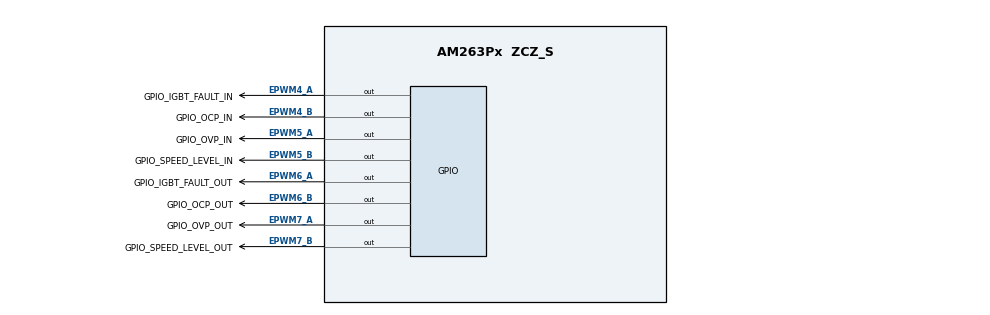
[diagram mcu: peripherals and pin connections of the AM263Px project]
/**
 * @cliArgs --device "AM263Px" --package "ZCZ_S" --part "AM263P4" --context "r5fss0-0" --product "MCU_PLUS_SDK@07.03.01"
 * @versions {"tool":"1.18.0+3266"}
 */

/**
 * Import the modules used in this configuration.
 */
const pmic            = scripting.addModule("/board/pmic/pmic", {}, false);
const pmic1           = pmic.addInstance();
const epwm            = scripting.addModule("/drivers/epwm/epwm", {}, false);
const epwm1           = epwm.addInstance();
const epwm2           = epwm.addInstance();
const epwm3           = epwm.addInstance();
const gpio            = scripting.addModule("/drivers/gpio/gpio", {}, false);
const gpio1           = gpio.addInstance();
const gpio2           = gpio.addInstance();
const gpio3           = gpio.addInstance();
const gpio4           = gpio.addInstance();
const gpio5           = gpio.addInstance();
const gpio6           = gpio.addInstance();
const gpio7           = gpio.addInstance();
const gpio8           = gpio.addInstance();
const mcspi           = scripting.addModule("/drivers/mcspi/mcspi", {}, false);
const mcspi1          = mcspi.addInstance();
const debug_log       = scripting.addModule("/kernel/dpl/debug_log");
const mpu_armv7       = scripting.addModule("/kernel/dpl/mpu_armv7", {}, false);
const mpu_armv71      = mpu_armv7.addInstance();
const mpu_armv72      = mpu_armv7.addInstance();
const mpu_armv73      = mpu_armv7.addInstance();
const mpu_armv74      = mpu_armv7.addInstance();
const default_linker  = scripting.addModule("/memory_configurator/default_linker", {}, false);
const default_linker1 = default_linker.addInstance();
const general         = scripting.addModule("/memory_configurator/general", {}, false);
const general1        = general.addInstance();
const region          = scripting.addModule("/memory_configurator/region", {}, false);
const region1         = region.addInstance();
const section         = scripting.addModule("/memory_configurator/section", {}, false);
const section1        = section.addInstance();
const section2        = section.addInstance();
const section3        = section.addInstance();
const section4        = section.addInstance();
const section5        = section.addInstance();
const section6        = section.addInstance();
const section7        = section.addInstance();
const section8        = section.addInstance();
const section9        = section.addInstance();
const section10       = section.addInstance();
const section11       = section.addInstance();
const section12       = section.addInstance();
const epwm_xbar       = scripting.addModule("/xbar/epwm_xbar/epwm_xbar", {}, false);
const epwm_xbar1      = epwm_xbar.addInstance();
const epwm_xbar2      = epwm_xbar.addInstance();
const epwm_xbar3      = epwm_xbar.addInstance();
const epwm_xbar4      = epwm_xbar.addInstance();
const epwm_xbar5      = epwm_xbar.addInstance();
const epwm_xbar6      = epwm_xbar.addInstance();
const epwm_xbar7      = epwm_xbar.addInstance();
const epwm_xbar8      = epwm_xbar.addInstance();
const int_xbar        = scripting.addModule("/xbar/int_xbar/int_xbar", {}, false);
const int_xbar1       = int_xbar.addInstance();

/**
 * Write custom configuration values to the imported modules.
 */
pmic1.$name = "CONFIG_PMIC0";

epwm1.epwmTimebase_emulationMode                               = "EPWM_EMULATION_FREE_RUN";
epwm1.epwmTimebase_period                                      = 10000;
epwm1.epwmTimebase_counterMode                                 = "EPWM_COUNTER_MODE_UP";
epwm1.epwmTimebase_syncOutPulseMode                            = ["EPWM_SYNC_OUT_PULSE_ON_ALL"];
epwm1.epwmCounterCompare_cmpA                                  = 7000;
epwm1.epwmCounterCompare_cmpB                                  = 7000;
epwm1.epwmActionQualifier_EPWM_AQ_OUTPUT_A_usedEvents          = ["EPWM_AQ_OUTPUT_ON_TIMEBASE_UP_CMPA","EPWM_AQ_OUTPUT_ON_TIMEBASE_ZERO"];
epwm1.epwmActionQualifier_EPWM_AQ_OUTPUT_B_usedEvents          = ["EPWM_AQ_OUTPUT_ON_TIMEBASE_UP_CMPB","EPWM_AQ_OUTPUT_ON_TIMEBASE_ZERO"];
epwm1.epwmActionQualifier_EPWM_AQ_OUTPUT_A_ON_TIMEBASE_ZERO    = "EPWM_AQ_OUTPUT_HIGH";
epwm1.epwmActionQualifier_EPWM_AQ_OUTPUT_A_ON_TIMEBASE_UP_CMPA = "EPWM_AQ_OUTPUT_LOW";
epwm1.epwmActionQualifier_EPWM_AQ_OUTPUT_B_ON_TIMEBASE_ZERO    = "EPWM_AQ_OUTPUT_LOW";
epwm1.epwmActionQualifier_EPWM_AQ_OUTPUT_B_ON_TIMEBASE_UP_CMPB = "EPWM_AQ_OUTPUT_HIGH";
epwm1.epwmEventTrigger_enableInterrupt                         = true;
epwm1.epwmEventTrigger_interruptEventCount                     = "1";
epwm1.epwmTripZone_EPWM_TZ_ACTION_EVENT_DCAEVT1                = "EPWM_TZ_ACTION_HIGH";
epwm1.epwmTripZone_EPWM_TZ_ACTION_EVENT_DCAEVT2                = "EPWM_TZ_ACTION_LOW";
epwm1.epwmTripZone_EPWM_TZ_ACTION_EVENT_DCBEVT1                = "EPWM_TZ_ACTION_HIGH";
epwm1.epwmTripZone_EPWM_TZ_ACTION_EVENT_DCBEVT2                = "EPWM_TZ_ACTION_LOW";
epwm1.epwmDigitalCompare_EPWM_TZ_DC_OUTPUT_A1                  = "EPWM_TZ_EVENT_DCXH_HIGH";
epwm1.epwmDigitalCompare_EPWM_TZ_DC_OUTPUT_A2                  = "EPWM_TZ_EVENT_DCXL_HIGH";
epwm1.epwmDigitalCompare_EPWM_TZ_DC_OUTPUT_B1                  = "EPWM_TZ_EVENT_DCXH_HIGH";
epwm1.epwmDigitalCompare_EPWM_TZ_DC_OUTPUT_B2                  = "EPWM_TZ_EVENT_DCXL_HIGH";
epwm1.epwmDigitalCompare_EPWM_DC_TYPE_DCAH                     = "EPWM_DC_TRIP_TRIPIN5";
epwm1.epwmDigitalCompare_EPWM_DC_TYPE_DCAL                     = "EPWM_DC_TRIP_TRIPIN6";
epwm1.epwmDigitalCompare_EPWM_DC_TYPE_DCBH                     = "EPWM_DC_TRIP_TRIPIN7";
epwm1.epwmDigitalCompare_EPWM_DC_TYPE_DCBL                     = "EPWM_DC_TRIP_TRIPIN8";
epwm1.$name                                                    = "CONFIG_PWM0";
epwm1.epwmDeadband_polarityFED                                 = "EPWM_DB_POLARITY_ACTIVE_LOW";
epwm1.epwmDeadband_enableRED                                   = true;
epwm1.epwmDeadband_enableFED                                   = true;
epwm1.epwmDeadband_delayRED                                    = 100;
epwm1.epwmDeadband_delayFED                                    = 100;
epwm1.EPWM.$assign                                             = "EPWM0";

epwm2.$name                                                    = "CONFIG_PWM1";
epwm2.epwmTimebase_counterMode                                 = "EPWM_COUNTER_MODE_UP";
epwm2.epwmTimebase_period                                      = 10000;
epwm2.epwmCounterCompare_cmpA                                  = 7000;
epwm2.epwmCounterCompare_cmpB                                  = 7000;
epwm2.epwmActionQualifier_EPWM_AQ_OUTPUT_A_usedEvents          = ["EPWM_AQ_OUTPUT_ON_TIMEBASE_UP_CMPA","EPWM_AQ_OUTPUT_ON_TIMEBASE_ZERO"];
epwm2.epwmActionQualifier_EPWM_AQ_OUTPUT_B_usedEvents          = ["EPWM_AQ_OUTPUT_ON_TIMEBASE_UP_CMPB","EPWM_AQ_OUTPUT_ON_TIMEBASE_ZERO"];
epwm2.epwmActionQualifier_EPWM_AQ_OUTPUT_A_ON_TIMEBASE_ZERO    = "EPWM_AQ_OUTPUT_HIGH";
epwm2.epwmActionQualifier_EPWM_AQ_OUTPUT_A_ON_TIMEBASE_UP_CMPA = "EPWM_AQ_OUTPUT_LOW";
epwm2.epwmActionQualifier_EPWM_AQ_OUTPUT_B_ON_TIMEBASE_ZERO    = "EPWM_AQ_OUTPUT_LOW";
epwm2.epwmActionQualifier_EPWM_AQ_OUTPUT_B_ON_TIMEBASE_UP_CMPB = "EPWM_AQ_OUTPUT_HIGH";
epwm2.epwmTripZone_EPWM_TZ_ACTION_EVENT_DCAEVT1                = "EPWM_TZ_ACTION_HIGH";
epwm2.epwmTripZone_EPWM_TZ_ACTION_EVENT_DCAEVT2                = "EPWM_TZ_ACTION_LOW";
epwm2.epwmTripZone_EPWM_TZ_ACTION_EVENT_DCBEVT1                = "EPWM_TZ_ACTION_HIGH";
epwm2.epwmTripZone_EPWM_TZ_ACTION_EVENT_DCBEVT2                = "EPWM_TZ_ACTION_LOW";
epwm2.epwmDigitalCompare_EPWM_TZ_DC_OUTPUT_A1                  = "EPWM_TZ_EVENT_DCXH_HIGH";
epwm2.epwmDigitalCompare_EPWM_TZ_DC_OUTPUT_A2                  = "EPWM_TZ_EVENT_DCXL_HIGH";
epwm2.epwmDigitalCompare_EPWM_TZ_DC_OUTPUT_B1                  = "EPWM_TZ_EVENT_DCXH_HIGH";
epwm2.epwmDigitalCompare_EPWM_TZ_DC_OUTPUT_B2                  = "EPWM_TZ_EVENT_DCXL_HIGH";
epwm2.epwmDigitalCompare_EPWM_DC_TYPE_DCAH                     = "EPWM_DC_TRIP_TRIPIN5";
epwm2.epwmDigitalCompare_EPWM_DC_TYPE_DCAL                     = "EPWM_DC_TRIP_TRIPIN6";
epwm2.epwmDigitalCompare_EPWM_DC_TYPE_DCBH                     = "EPWM_DC_TRIP_TRIPIN7";
epwm2.epwmDigitalCompare_EPWM_DC_TYPE_DCBL                     = "EPWM_DC_TRIP_TRIPIN8";
epwm2.epwmDeadband_polarityFED                                 = "EPWM_DB_POLARITY_ACTIVE_LOW";
epwm2.epwmDeadband_enableRED                                   = true;
epwm2.epwmDeadband_enableFED                                   = true;
epwm2.epwmDeadband_delayRED                                    = 100;
epwm2.epwmDeadband_delayFED                                    = 100;
epwm2.EPWM.$assign                                             = "EPWM1";

epwm3.$name                                                    = "CONFIG_PWM2";
epwm3.epwmTimebase_counterMode                                 = "EPWM_COUNTER_MODE_UP";
epwm3.epwmTimebase_period                                      = 10000;
epwm3.epwmCounterCompare_cmpA                                  = 7000;
epwm3.epwmCounterCompare_cmpB                                  = 7000;
epwm3.epwmActionQualifier_EPWM_AQ_OUTPUT_A_usedEvents          = ["EPWM_AQ_OUTPUT_ON_TIMEBASE_UP_CMPA","EPWM_AQ_OUTPUT_ON_TIMEBASE_ZERO"];
epwm3.epwmActionQualifier_EPWM_AQ_OUTPUT_B_usedEvents          = ["EPWM_AQ_OUTPUT_ON_TIMEBASE_UP_CMPB","EPWM_AQ_OUTPUT_ON_TIMEBASE_ZERO"];
epwm3.epwmActionQualifier_EPWM_AQ_OUTPUT_A_ON_TIMEBASE_ZERO    = "EPWM_AQ_OUTPUT_HIGH";
epwm3.epwmActionQualifier_EPWM_AQ_OUTPUT_A_ON_TIMEBASE_UP_CMPA = "EPWM_AQ_OUTPUT_LOW";
epwm3.epwmActionQualifier_EPWM_AQ_OUTPUT_B_ON_TIMEBASE_ZERO    = "EPWM_AQ_OUTPUT_LOW";
epwm3.epwmActionQualifier_EPWM_AQ_OUTPUT_B_ON_TIMEBASE_UP_CMPB = "EPWM_AQ_OUTPUT_HIGH";
epwm3.epwmTripZone_EPWM_TZ_ACTION_EVENT_DCAEVT1                = "EPWM_TZ_ACTION_HIGH";
epwm3.epwmTripZone_EPWM_TZ_ACTION_EVENT_DCAEVT2                = "EPWM_TZ_ACTION_LOW";
epwm3.epwmTripZone_EPWM_TZ_ACTION_EVENT_DCBEVT1                = "EPWM_TZ_ACTION_HIGH";
epwm3.epwmTripZone_EPWM_TZ_ACTION_EVENT_DCBEVT2                = "EPWM_TZ_ACTION_LOW";
epwm3.epwmDigitalCompare_EPWM_TZ_DC_OUTPUT_A1                  = "EPWM_TZ_EVENT_DCXH_HIGH";
epwm3.epwmDigitalCompare_EPWM_TZ_DC_OUTPUT_A2                  = "EPWM_TZ_EVENT_DCXL_HIGH";
epwm3.epwmDigitalCompare_EPWM_TZ_DC_OUTPUT_B1                  = "EPWM_TZ_EVENT_DCXH_HIGH";
epwm3.epwmDigitalCompare_EPWM_TZ_DC_OUTPUT_B2                  = "EPWM_TZ_EVENT_DCXL_HIGH";
epwm3.epwmDigitalCompare_EPWM_DC_TYPE_DCAH                     = "EPWM_DC_TRIP_TRIPIN5";
epwm3.epwmDigitalCompare_EPWM_DC_TYPE_DCAL                     = "EPWM_DC_TRIP_TRIPIN6";
epwm3.epwmDigitalCompare_EPWM_DC_TYPE_DCBH                     = "EPWM_DC_TRIP_TRIPIN7";
epwm3.epwmDigitalCompare_EPWM_DC_TYPE_DCBL                     = "EPWM_DC_TRIP_TRIPIN8";
epwm3.epwmDeadband_polarityFED                                 = "EPWM_DB_POLARITY_ACTIVE_LOW";
epwm3.epwmDeadband_enableRED                                   = true;
epwm3.epwmDeadband_enableFED                                   = true;
epwm3.epwmDeadband_delayRED                                    = 100;
epwm3.epwmDeadband_delayFED                                    = 100;
epwm3.EPWM.$assign                                             = "EPWM2";

gpio1.$name                = "GPIO_IGBT_FAULT_IN";
gpio1.GPIO.gpioPin.$assign = "EPWM4_A";

gpio2.$name                = "GPIO_OVP_IN";
gpio2.GPIO.$assign         = "GPIO";
gpio2.GPIO.gpioPin.$assign = "EPWM5_A";

gpio3.pinDir               = "OUTPUT";
gpio3.$name                = "GPIO_IGBT_FAULT_OUT";
gpio3.GPIO.$assign         = "GPIO";
gpio3.GPIO.gpioPin.$assign = "EPWM6_A";

gpio4.pinDir               = "OUTPUT";
gpio4.$name                = "GPIO_OVP_OUT";
gpio4.GPIO.$assign         = "GPIO";
gpio4.GPIO.gpioPin.$assign = "EPWM7_A";

gpio5.$name                = "GPIO_OCP_IN";
gpio5.GPIO.$assign         = "GPIO";
gpio5.GPIO.gpioPin.$assign = "EPWM4_B";

gpio6.$name                = "GPIO_SPEED_LEVEL_IN";
gpio6.GPIO.$assign         = "GPIO";
gpio6.GPIO.gpioPin.$assign = "EPWM5_B";

gpio7.pinDir               = "OUTPUT";
gpio7.$name                = "GPIO_OCP_OUT";
gpio7.GPIO.$assign         = "GPIO";
gpio7.GPIO.gpioPin.$assign = "EPWM6_B";

gpio8.pinDir               = "OUTPUT";
gpio8.$name                = "GPIO_SPEED_LEVEL_OUT";
gpio8.GPIO.$assign         = "GPIO";
gpio8.GPIO.gpioPin.$assign = "EPWM7_B";

mcspi1.$name                 = "CONFIG_MCSPI0";
pmic1.peripheralDriver       = mcspi1;
mcspi1.SPI.$assign           = "SPI1";
mcspi1.mcspiChannel[0].$name = "CONFIG_MCSPI_CH0";

const edma                  = scripting.addModule("/drivers/edma/edma", {}, false);
const edma1                 = edma.addInstance({}, false);
edma1.$name                 = "CONFIG_EDMA0";
mcspi1.edmaDriver           = edma1;
edma1.edmaRmDmaCh[0].$name  = "CONFIG_EDMA_RM0";
edma1.edmaRmQdmaCh[0].$name = "CONFIG_EDMA_RM1";
edma1.edmaRmTcc[0].$name    = "CONFIG_EDMA_RM2";
edma1.edmaRmParam[0].$name  = "CONFIG_EDMA_RM3";

debug_log.enableUartLog            = true;
debug_log.uartLog.$name            = "CONFIG_UART0";
debug_log.uartLog.UART.RXD.$assign = "UART0_RXD";
debug_log.uartLog.UART.TXD.$assign = "UART0_TXD";

mpu_armv71.$name             = "CONFIG_MPU_REGION0";
mpu_armv71.size              = 31;
mpu_armv71.attributes        = "Device";
mpu_armv71.accessPermissions = "Supervisor RD+WR, User RD";
mpu_armv71.allowExecute      = false;

mpu_armv72.$name             = "CONFIG_MPU_REGION1";
mpu_armv72.size              = 15;
mpu_armv72.accessPermissions = "Supervisor RD+WR, User RD";

mpu_armv73.$name             = "CONFIG_MPU_REGION2";
mpu_armv73.baseAddr          = 0x80000;
mpu_armv73.size              = 15;
mpu_armv73.accessPermissions = "Supervisor RD+WR, User RD";

mpu_armv74.$name             = "CONFIG_MPU_REGION3";
mpu_armv74.accessPermissions = "Supervisor RD+WR, User RD";
mpu_armv74.baseAddr          = 0x70000000;
mpu_armv74.size              = 21;

default_linker1.$name = "memory_configurator_default_linker0";

general1.$name        = "CONFIG_GENERAL0";
general1.linker.$name = "TIARMCLANG0";

region1.$name                                = "MEMORY_REGION_CONFIGURATION0";
region1.memory_region.create(11);
region1.memory_region[0].type                = "TCMA";
region1.memory_region[0].$name               = "R5F_VECS";
region1.memory_region[0].size                = 0x40;
region1.memory_region[0].auto                = false;
region1.memory_region[1].type                = "TCMA";
region1.memory_region[1].$name               = "R5F_TCMA";
region1.memory_region[1].size                = 0x7FC0;
region1.memory_region[2].type                = "TCMB";
region1.memory_region[2].size                = 0x8000;
region1.memory_region[2].$name               = "R5F_TCMB";
region1.memory_region[3].$name               = "SBL";
region1.memory_region[3].auto                = false;
region1.memory_region[3].size                = 0x40000;
region1.memory_region[4].$name               = "OCRAM";
region1.memory_region[4].auto                = false;
region1.memory_region[4].manualStartAddress  = 0x70040000;
region1.memory_region[4].size                = 0x40000;
region1.memory_region[5].type                = "FLASH";
region1.memory_region[5].auto                = false;
region1.memory_region[5].manualStartAddress  = 0x60100000;
region1.memory_region[5].size                = 0x80000;
region1.memory_region[5].$name               = "FLASH";
region1.memory_region[6].$name               = "USER_SHM_MEM";
region1.memory_region[6].auto                = false;
region1.memory_region[6].manualStartAddress  = 0x701D0000;
region1.memory_region[6].size                = 0x4000;
region1.memory_region[6].isShared            = true;
region1.memory_region[6].shared_cores        = ["r5fss0-1","r5fss1-0","r5fss1-1"];
region1.memory_region[7].$name               = "LOG_SHM_MEM";
region1.memory_region[7].auto                = false;
region1.memory_region[7].manualStartAddress  = 0x701D4000;
region1.memory_region[7].size                = 0x4000;
region1.memory_region[7].isShared            = true;
region1.memory_region[7].shared_cores        = ["r5fss0-1","r5fss1-0","r5fss1-1"];
region1.memory_region[8].type                = "CUSTOM";
region1.memory_region[8].$name               = "RTOS_NORTOS_IPC_SHM_MEM";
region1.memory_region[8].auto                = false;
region1.memory_region[8].manualStartAddress  = 0x72000000;
region1.memory_region[8].size                = 0x3E80;
region1.memory_region[8].isShared            = true;
region1.memory_region[8].shared_cores        = ["r5fss0-1","r5fss1-0","r5fss1-1"];
region1.memory_region[9].type                = "CUSTOM";
region1.memory_region[9].$name               = "MAILBOX_HSM";
region1.memory_region[9].auto                = false;
region1.memory_region[9].manualStartAddress  = 0x44000000;
region1.memory_region[9].size                = 0x3CE;
region1.memory_region[9].isShared            = true;
region1.memory_region[9].shared_cores        = ["r5fss0-1","r5fss1-0","r5fss1-1"];
region1.memory_region[10].type               = "CUSTOM";
region1.memory_region[10].$name              = "MAILBOX_R5F";
region1.memory_region[10].auto               = false;
region1.memory_region[10].manualStartAddress = 0x44000400;
region1.memory_region[10].size               = 0x3CE;
region1.memory_region[10].isShared           = true;
region1.memory_region[10].shared_cores       = ["r5fss0-1","r5fss1-0","r5fss1-1"];

section1.load_memory                  = "R5F_VECS";
section1.group                        = false;
section1.$name                        = "Vector Table";
section1.output_section.create(1);
section1.output_section[0].$name      = ".vectors";
section1.output_section[0].palignment = true;

section2.load_memory                  = "OCRAM";
section2.$name                        = "Text Segments";
section2.output_section.create(5);
section2.output_section[0].$name      = ".text.hwi";
section2.output_section[0].palignment = true;
section2.output_section[1].$name      = ".text.cache";
section2.output_section[1].palignment = true;
section2.output_section[2].$name      = ".text.mpu";
section2.output_section[2].palignment = true;
section2.output_section[3].$name      = ".text.boot";
section2.output_section[3].palignment = true;
section2.output_section[4].$name      = ".text:abort";
section2.output_section[4].palignment = true;

section3.load_memory                  = "OCRAM";
section3.$name                        = "Code and Read-Only Data";
section3.output_section.create(2);
section3.output_section[0].$name      = ".text";
section3.output_section[0].palignment = true;
section3.output_section[1].$name      = ".rodata";
section3.output_section[1].palignment = true;

section4.load_memory                  = "OCRAM";
section4.$name                        = "Data Segment";
section4.output_section.create(1);
section4.output_section[0].$name      = ".data";
section4.output_section[0].palignment = true;

section5.load_memory                             = "OCRAM";
section5.$name                                   = "Memory Segments";
section5.output_section.create(3);
section5.output_section[0].$name                 = ".bss";
section5.output_section[0].output_sections_start = "__BSS_START";
section5.output_section[0].output_sections_end   = "__BSS_END";
section5.output_section[0].palignment            = true;
section5.output_section[1].$name                 = ".sysmem";
section5.output_section[1].palignment            = true;
section5.output_section[2].$name                 = ".stack";
section5.output_section[2].palignment            = true;

section6.load_memory                              = "OCRAM";
section6.$name                                    = "Stack Segments";
section6.output_section.create(5);
section6.output_section[0].$name                  = ".irqstack";
section6.output_section[0].output_sections_start  = "__IRQ_STACK_START";
section6.output_section[0].output_sections_end    = "__IRQ_STACK_END";
section6.output_section[0].input_section.create(1);
section6.output_section[0].input_section[0].$name = ". = . + __IRQ_STACK_SIZE;";
section6.output_section[1].$name                  = ".fiqstack";
section6.output_section[1].output_sections_start  = "__FIQ_STACK_START";
section6.output_section[1].output_sections_end    = "__FIQ_STACK_END";
section6.output_section[1].input_section.create(1);
section6.output_section[1].input_section[0].$name = ". = . + __FIQ_STACK_SIZE;";
section6.output_section[2].$name                  = ".svcstack";
section6.output_section[2].output_sections_start  = "__SVC_STACK_START";
section6.output_section[2].output_sections_end    = "__SVC_STACK_END";
section6.output_section[2].input_section.create(1);
section6.output_section[2].input_section[0].$name = ". = . + __SVC_STACK_SIZE;";
section6.output_section[3].$name                  = ".abortstack";
section6.output_section[3].output_sections_start  = "__ABORT_STACK_START";
section6.output_section[3].output_sections_end    = "__ABORT_STACK_END";
section6.output_section[3].input_section.create(1);
section6.output_section[3].input_section[0].$name = ". = . + __ABORT_STACK_SIZE;";
section6.output_section[4].$name                  = ".undefinedstack";
section6.output_section[4].output_sections_start  = "__UNDEFINED_STACK_START";
section6.output_section[4].output_sections_end    = "__UNDEFINED_STACK_END";
section6.output_section[4].input_section.create(1);
section6.output_section[4].input_section[0].$name = ". = . + __UNDEFINED_STACK_SIZE;";

section7.load_memory                  = "OCRAM";
section7.$name                        = "Initialization and Exception Handling";
section7.output_section.create(3);
section7.output_section[0].$name      = ".ARM.exidx";
section7.output_section[0].palignment = true;
section7.output_section[1].$name      = ".init_array";
section7.output_section[1].palignment = true;
section7.output_section[2].$name      = ".fini_array";
section7.output_section[2].palignment = true;

section8.load_memory                 = "USER_SHM_MEM";
section8.type                        = "NOLOAD";
section8.$name                       = "User Shared Memory";
section8.group                       = false;
section8.output_section.create(1);
section8.output_section[0].$name     = ".bss.user_shared_mem";
section8.output_section[0].alignment = 0;

section9.load_memory                 = "LOG_SHM_MEM";
section9.$name                       = "Log Shared Memory";
section9.group                       = false;
section9.type                        = "NOLOAD";
section9.output_section.create(1);
section9.output_section[0].$name     = ".bss.log_shared_mem";
section9.output_section[0].alignment = 0;

section10.load_memory                 = "RTOS_NORTOS_IPC_SHM_MEM";
section10.type                        = "NOLOAD";
section10.$name                       = "IPC Shared Memory";
section10.group                       = false;
section10.output_section.create(1);
section10.output_section[0].$name     = ".bss.ipc_vring_mem";
section10.output_section[0].alignment = 0;

section11.load_memory                 = "MAILBOX_HSM";
section11.type                        = "NOLOAD";
section11.$name                       = "SIPC HSM Queue Memory";
section11.group                       = false;
section11.output_section.create(1);
section11.output_section[0].$name     = ".bss.sipc_hsm_queue_mem";
section11.output_section[0].alignment = 0;

section12.load_memory                 = "MAILBOX_R5F";
section12.$name                       = "SIPC R5F Queue Memory";
section12.group                       = false;
section12.type                        = "NOLOAD";
section12.output_section.create(1);
section12.output_section[0].$name     = ".bss.sipc_r5f_queue_mem";
section12.output_section[0].alignment = 0;

epwm_xbar1.$name                 = "CONFIG_EPWM_XBAR0_INPUTXBAR_TO_ICSSGPI";
epwm_xbar1.xbarOutput            = ["GPIO51"];
epwm_xbar1["xbarConfig-0"].$name = "CONFIG_INPUT_XBAR0";

epwm_xbar2.instance                 = "EPWM_XBAR_1";
epwm_xbar2.$name                    = "CONFIG_EPWM_XBAR1_INPUTXBAR_TO_ICSSGPI";
epwm_xbar2.xbarOutput               = ["GPIO52"];
epwm_xbar2["xbarConfig-0"].$name    = "CONFIG_INPUT_XBAR1";
epwm_xbar2["xbarConfig-0"].instance = "INPUT_XBAR_1";

epwm_xbar3.instance                 = "EPWM_XBAR_2";
epwm_xbar3.$name                    = "CONFIG_EPWM_XBAR2_INPUTXBAR_TO_ICSSGPI";
epwm_xbar3.xbarOutput               = ["GPIO53"];
epwm_xbar3["xbarConfig-0"].$name    = "CONFIG_INPUT_XBAR2";
epwm_xbar3["xbarConfig-0"].instance = "INPUT_XBAR_2";

epwm_xbar4.instance                 = "EPWM_XBAR_3";
epwm_xbar4.$name                    = "CONFIG_EPWM_XBAR3_INPUTXBAR_TO_ICSSGPI";
epwm_xbar4.xbarOutput               = ["GPIO54"];
epwm_xbar4["xbarConfig-0"].$name    = "CONFIG_INPUT_XBAR3";
epwm_xbar4["xbarConfig-0"].instance = "INPUT_XBAR_3";

epwm_xbar5.xbarOutput               = ["ICSSGPO0_PORT0"];
epwm_xbar5.instance                 = "EPWM_XBAR_4";
epwm_xbar5.$name                    = "CONFIG_EPWM_XBAR4_INPUTXBAR_TO_EPWM";
epwm_xbar5["xbarConfig-0"].instance = "INPUT_XBAR_4";
epwm_xbar5["xbarConfig-0"].$name    = "CONFIG_INPUT_XBAR4_ICSSGPO_TO_PWMXBAR";

epwm_xbar6.xbarOutput               = ["ICSSGPO1_PORT0"];
epwm_xbar6.instance                 = "EPWM_XBAR_5";
epwm_xbar6.$name                    = "CONFIG_EPWM_XBAR5_INPUTXBAR_TO_EPWM";
epwm_xbar6["xbarConfig-0"].instance = "INPUT_XBAR_5";
epwm_xbar6["xbarConfig-0"].$name    = "CONFIG_INPUT_XBAR5_ICSSGPO_TO_PWMXBAR";

epwm_xbar7.xbarOutput               = ["ICSSGPO2_PORT0"];
epwm_xbar7.instance                 = "EPWM_XBAR_6";
epwm_xbar7.$name                    = "CONFIG_EPWM_XBAR6_INPUTXBAR_TO_EPWM";
epwm_xbar7["xbarConfig-0"].instance = "INPUT_XBAR_6";
epwm_xbar7["xbarConfig-0"].$name    = "CONFIG_INPUT_XBAR6_ICSSGPO_TO_PWMXBAR";

epwm_xbar8.xbarOutput               = ["ICSSGPO3_PORT0"];
epwm_xbar8.instance                 = "EPWM_XBAR_7";
epwm_xbar8.$name                    = "CONFIG_EPWM_XBAR7_INPUTXBAR_TO_EPWM";
epwm_xbar8["xbarConfig-0"].instance = "INPUT_XBAR_7";
epwm_xbar8["xbarConfig-0"].$name    = "CONFIG_INPUT_XBAR7_ICSSGPO_TO_PWMXBAR";

int_xbar1.$name      = "CONFIG_INT_XBAR0";
int_xbar1.xbarOutput = ["EPWM9_INT"];

/**
 * Pinmux solution for unlocked pins/peripherals. This ensures that minor changes to the automatic solver in a future
 * version of the tool will not impact the pinmux you originally saw.  These lines can be completely deleted in order to
 * re-solve from scratch.
 */
epwm1.EPWM.A.$suggestSolution               = "EPWM0_A";
epwm1.EPWM.B.$suggestSolution               = "EPWM0_B";
epwm2.EPWM.A.$suggestSolution               = "EPWM1_A";
epwm2.EPWM.B.$suggestSolution               = "EPWM1_B";
epwm3.EPWM.A.$suggestSolution               = "EPWM2_A";
epwm3.EPWM.B.$suggestSolution               = "EPWM2_B";
gpio1.GPIO.$suggestSolution                 = "GPIO";
mcspi1.SPI.CLK.$suggestSolution             = "SPI1_CLK";
mcspi1.SPI.D0.$suggestSolution              = "SPI1_D0";
mcspi1.SPI.D1.$suggestSolution              = "SPI1_D1";
mcspi1.mcspiChannel[0].CSn.$suggestSolution = "SPI1_CS0";
debug_log.uartLog.UART.$suggestSolution     = "UART0";
